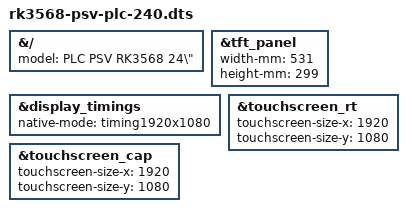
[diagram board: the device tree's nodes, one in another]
/dts-v1/;
/plugin/;

#include "rk3568-psv-plc_bb12.dtsi"

&{/} {
    model = "PLC PSV RK3568 24\"";
};

&tft_panel {
    width-mm = <531>;
    height-mm = <299>;
};

&display_timings {
    native-mode = <&timing1920x1080>;
};

&touchscreen_rt {
        touchscreen-size-x = <1920>;
        touchscreen-size-y = <1080>;
};

&touchscreen_cap {
        touchscreen-size-x = <1920>;
        touchscreen-size-y = <1080>;
};
